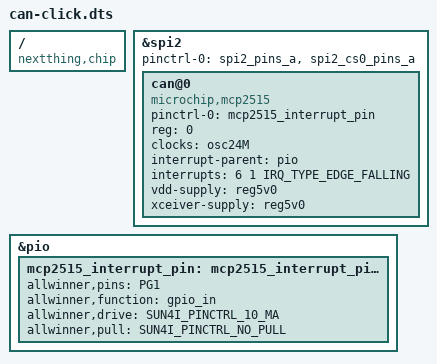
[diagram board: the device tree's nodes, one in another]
/*
 * Copyright 2017 cozmIC
 *
 * Pierre-Jean TEXIER <pjtexier@cozmic.co>
 *
 * This file is dual-licensed: you can use it either under the terms
 * of the GPL or the X11 license, at your option. Note that this dual
 * licensing only applies to this file, and not this project as a
 * whole.
 *
 *  a) This file is free software; you can redistribute it and/or
 *     modify it under the terms of the GNU General Public License as
 *     published by the Free Software Foundation; either version 2 of the
 *     License, or (at your option) any later version.
 *
 *     This file is distributed in the hope that it will be useful,
 *     but WITHOUT ANY WARRANTY; without even the implied warranty of
 *     MERCHANTABILITY or FITNESS FOR A PARTICULAR PURPOSE.  See the
 *     GNU General Public License for more details.
 *
 * Or, alternatively,
 *
 *  b) Permission is hereby granted, free of charge, to any person
 *     obtaining a copy of this software and associated documentation
 *     files (the "Software"), to deal in the Software without
 *     restriction, including without limitation the rights to use,
 *     copy, modify, merge, publish, distribute, sublicense, and/or
 *     sell copies of the Software, and to permit persons to whom the
 *     Software is furnished to do so, subject to the following
 *     conditions:
 *
 *     The above copyright notice and this permission notice shall be
 *     included in all copies or substantial portions of the Software.
 *
 *     THE SOFTWARE IS PROVIDED "AS IS", WITHOUT WARRANTY OF ANY KIND,
 *     EXPRESS OR IMPLIED, INCLUDING BUT NOT LIMITED TO THE WARRANTIES
 *     OF MERCHANTABILITY, FITNESS FOR A PARTICULAR PURPOSE AND
 *     NONINFRINGEMENT. IN NO EVENT SHALL THE AUTHORS OR COPYRIGHT
 *     HOLDERS BE LIABLE FOR ANY CLAIM, DAMAGES OR OTHER LIABILITY,
 *     WHETHER IN AN ACTION OF CONTRACT, TORT OR OTHERWISE, ARISING
 *     FROM, OUT OF OR IN CONNECTION WITH THE SOFTWARE OR THE USE OR
 *     OTHER DEALINGS IN THE SOFTWARE.
 */

/dts-v1/;
/plugin/;

#include <dt-bindings/gpio/gpio.h>
#include <dt-bindings/pinctrl/sun4i-a10.h>
#include <dt-bindings/interrupt-controller/irq.h>

/ {
	compatible = "nextthing,chip", "allwinner,sun5i-r8";

	fragment@0 {
	
		target = <&spi2>;

		__overlay__ {
		
			pinctrl-names = "default";
			pinctrl-0 = <&spi2_pins_a>,
				    <&spi2_cs0_pins_a>;
			status = "okay";
			#address-cells = <1>;
			#size-cells = <0>;

			can@0 {
	 	                compatible = "microchip,mcp2515";
	 			pinctrl-names = "default";
				pinctrl-0 = <&mcp2515_interrupt_pin>;
				reg = <0>;
				clocks = <&osc24M>;
				interrupt-parent = <&pio>;
				interrupts = <6 1 IRQ_TYPE_EDGE_FALLING>;
				vdd-supply = <&reg5v0>;
				xceiver-supply = <&reg5v0>;
          		};						
		};
	};
	
	fragment@1 {
	
		target = <&pio>;
		
		__overlay__ {
		
			mcp2515_interrupt_pin: mcp2515_interrupt_pin@0 {
				allwinner,pins = "PG1";
				allwinner,function = "gpio_in";
				allwinner,drive = <SUN4I_PINCTRL_10_MA>;
				allwinner,pull = <SUN4I_PINCTRL_NO_PULL>;
			};
		};
	};

};

